# STM32WLE5_CM4 register map
File version: 1.0
CPU: CM4 r0p1, little endian, MPU, FPU, 4 interrupt priority bits
Registers are 32-bit, read-write, reset 0x0 unless marked. A register's access mark holds for its fields unless they carry their own. Offsets are from the block's base; [hi:lo] are bit positions; {n}, {i} and the like mark numbered series; 'fields as' and 'values as' point back to an identical list.

## HSEM — Hardware semaphore
Base 0x58001400
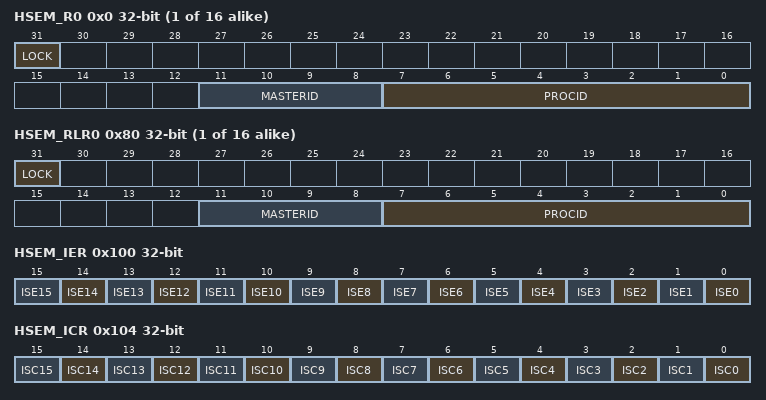
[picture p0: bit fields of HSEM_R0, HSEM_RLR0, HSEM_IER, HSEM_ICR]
{0x0+4i} HSEM_R{i} (i=0..15) — HSEM register HSEM_R0 HSEM_R31
  [31] LOCK — Lock indication
  [11:8] MASTERID — Semaphore MASTERID
  [7:0] PROCID — Semaphore ProcessID
{0x80+4i} HSEM_RLR{i} ro (i=0..15) — HSEM Read lock register
  fields as HSEM_R0
0x100 HSEM_IER — HSEM Interrupt enable register
  [n] ISE{n} (n=0..15) — Interrupt semaphore n enable bit
0x104 HSEM_ICR — HSEM Interrupt clear register
  [n] ISC{n} (n=0..15) — Interrupt(N) semaphore n clear bit
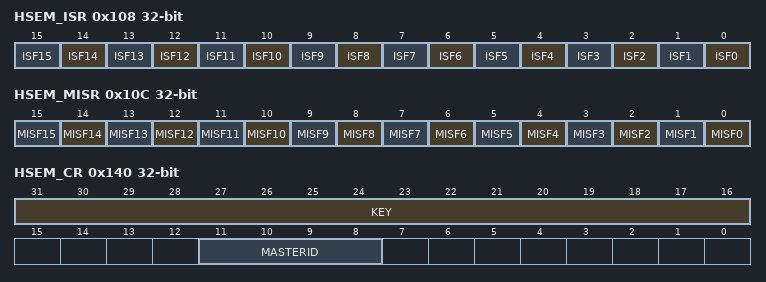
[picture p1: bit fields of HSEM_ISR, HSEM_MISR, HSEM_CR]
0x108 HSEM_ISR ro — HSEM Interrupt status register
  [n] ISF{n} (n=0..15) — Interrupt(N) semaphore n status bit before enable (mask)
0x10C HSEM_MISR ro — HSEM Masked interrupt status register
  [n] MISF{n} (n=0..15) — masked interrupt(N) semaphore n status bit after enable (mask)
0x140 HSEM_CR wo — HSEM Clear register
  [31:16] KEY — Semaphore clear Key
  [11:8] MASTERID
0x144 HSEM_KEYR — HSEM Interrupt clear register
  [31:16] KEY — Semaphore Clear Key

## ADC — Analog to digital convertor
Base 0x40012400
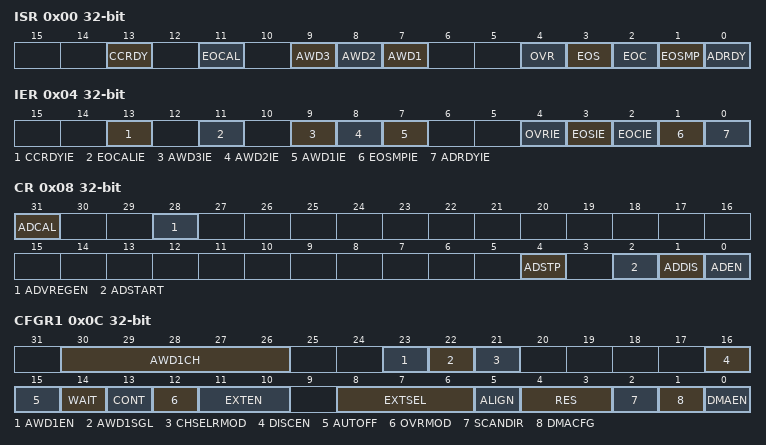
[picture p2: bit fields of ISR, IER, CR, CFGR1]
0x00 ISR — ADC interrupt and status register
  [13] CCRDY, [11] EOCAL, [9] AWD3, [8] AWD2, [7] AWD1, [4] OVR, [3] EOS, [2] EOC, [1] EOSMP, [0] ADRDY
0x04 IER — ADC interrupt enable register
  [13] CCRDYIE, [11] EOCALIE, [9] AWD3IE, [8] AWD2IE, [7] AWD1IE, [4] OVRIE, [3] EOSIE, [2] EOCIE, [1] EOSMPIE, [0] ADRDYIE
0x08 CR — ADC control register
  [31] ADCAL, [28] ADVREGEN, [4] ADSTP, [2] ADSTART, [1] ADDIS, [0] ADEN
0x0C CFGR1 — ADC configuration register 1
  [30:26] AWD1CH, [23] AWD1EN, [22] AWD1SGL, [21] CHSELRMOD, [16] DISCEN, [15] AUTOFF, [14] WAIT, [13] CONT, [12] OVRMOD, [11:10] EXTEN, [8:6] EXTSEL, [5] ALIGN, [4:3] RES, [2] SCANDIR, [1] DMACFG, [0] DMAEN
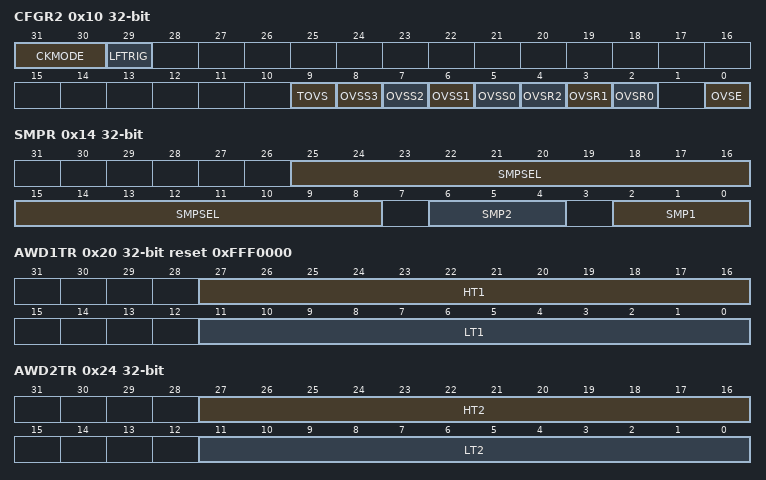
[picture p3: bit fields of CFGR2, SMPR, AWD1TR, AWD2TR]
0x10 CFGR2 — ADC configuration register 2
  [31:30] CKMODE, [29] LFTRIG, [9] TOVS, [n+5] OVSS{n} (n=0..3), [4] OVSR2, [3] OVSR1, [2] OVSR0, [0] OVSE
0x14 SMPR — ADC sampling time register
  [25:8] SMPSEL, [6:4] SMP2, [2:0] SMP1
0x20 AWD1TR reset 0xFFF0000 — ADC watchdog threshold register
  [27:16] HT1, [11:0] LT1
0x24 AWD2TR — ADC watchdog threshold register
  [27:16] HT2, [11:0] LT2
0x28 CHSELR0 — channel selection register
  [17:0] CHSEL
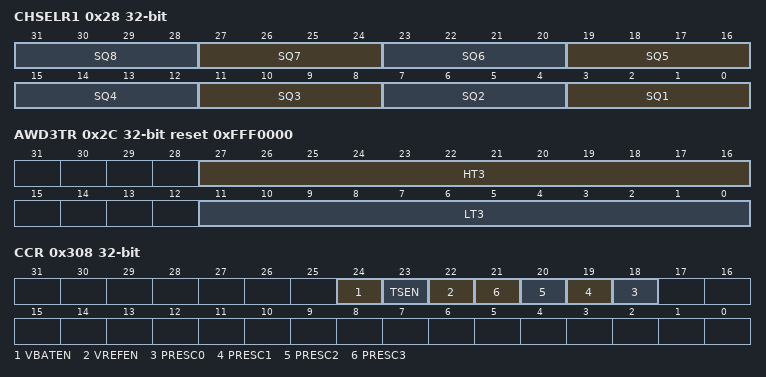
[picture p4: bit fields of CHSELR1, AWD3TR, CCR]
0x28 CHSELR1 (alternate view of CHSELR0) — channel selection register
  [4n-1:4n-4] SQ{n} (n=1..8)
0x2C AWD3TR reset 0xFFF0000 — ADC watchdog threshold register
  [27:16] HT3, [11:0] LT3
0x40 DR ro — ADC data register
  [15:0] DATA
0xA0 AWD2CR — ADC Analog Watchdog 2 Configuration register
  [17:0] AWD2CH
0xA4 AWD3CR — ADC Analog Watchdog 3 Configuration register
  [17:0] AWD3CH
0xB4 CALFACT — ADC Calibration factor
  [6:0] CALFACT
0x308 CCR — ADC common configuration register
  [24] VBATEN, [23] TSEN, [22] VREFEN, [n+18] PRESC{n} (n=0..3)

## GPIOA — General-purpose I/Os
Base 0x48000000
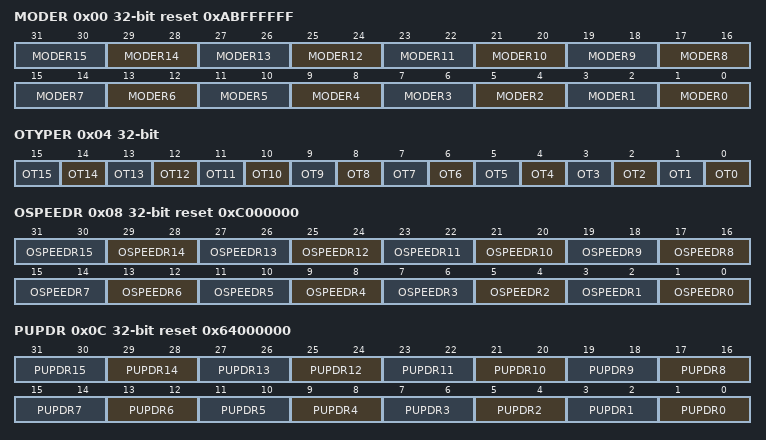
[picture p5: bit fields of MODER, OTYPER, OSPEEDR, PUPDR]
0x00 MODER reset 0xABFFFFFF — GPIO port mode register
  [2n+1:2n] MODER{n} (n=0..15)
0x04 OTYPER — GPIO port output type register
  [n] OT{n} (n=0..15) — Port x configuration bits (y = 0..15)
0x08 OSPEEDR reset 0xC000000 — GPIO port output speed register
  [2n+1:2n] OSPEEDR{n} (n=0..15) — Port x configuration bits (y = 0..15)
0x0C PUPDR reset 0x64000000 — GPIO port pull-up/pull-down register
  [2n+1:2n] PUPDR{n} (n=0..15) — Port x configuration bits (y = 0..15)
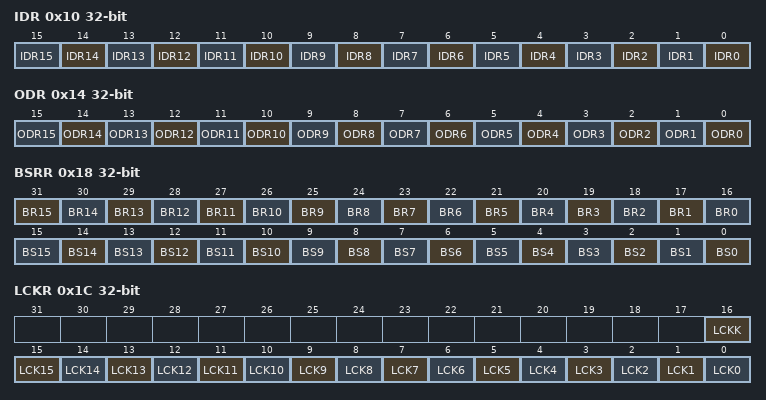
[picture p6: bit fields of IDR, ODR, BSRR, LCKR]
0x10 IDR ro — GPIO port input data register
  [n] IDR{n} (n=0..15) — Port input data (y = 0..15)
0x14 ODR — GPIO port output data register
  [n] ODR{n} (n=0..15) — Port output data (y = 0..15)
0x18 BSRR wo — GPIO port bit set/reset register
  [n+16] BR{n} (n=1..15) — Port x reset bit y (y = 0..15)
  [16] BR0 — Port x set bit y (y= 0..15)
  [n] BS{n} (n=0..15) — Port x set bit y (y= 0..15)
0x1C LCKR — GPIO port configuration lock register
  [16] LCKK — Port x lock bit y (y= 0..15)
  [n] LCK{n} (n=0..15) — Port x lock bit y (y= 0..15)
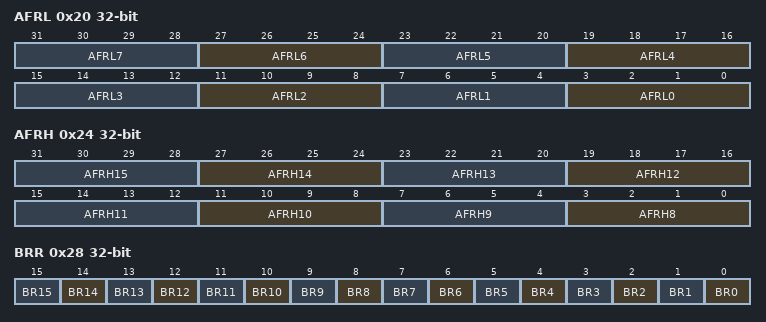
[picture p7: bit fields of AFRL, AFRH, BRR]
0x20 AFRL — GPIO alternate function low register
  [4n+3:4n] AFRL{n} (n=0..7) — Alternate function selection for port x bit y (y = 0..7)
0x24 AFRH — GPIO alternate function high register
  [4n-29:4n-32] AFRH{n} (n=8..15) — Alternate function selection for port x bit y (y = 8..15)
0x28 BRR — GPIO port bit reset register
  [n] BR{n} (n=0..15) — Port Reset bit

## GPIOB — General-purpose I/Os
Base 0x48000400
Registers as GPIOA; these are added or differ:
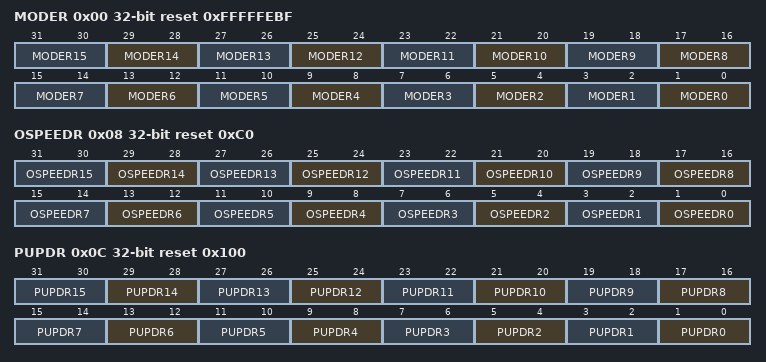
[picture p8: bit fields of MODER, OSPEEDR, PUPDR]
0x00 MODER reset 0xFFFFFEBF — GPIO port mode register
  [2n+1:2n] MODER{n} (n=0..15) — Port x configuration bits (y = 0..15)
0x08 OSPEEDR reset 0xC0 — GPIO port output speed register
  [2n+1:2n] OSPEEDR{n} (n=0..15) — Port x configuration bits (y = 0..15)
0x0C PUPDR reset 0x100 — GPIO port pull-up/pull-down register
  [2n+1:2n] PUPDR{n} (n=0..15) — Port x configuration bits (y = 0..15)
